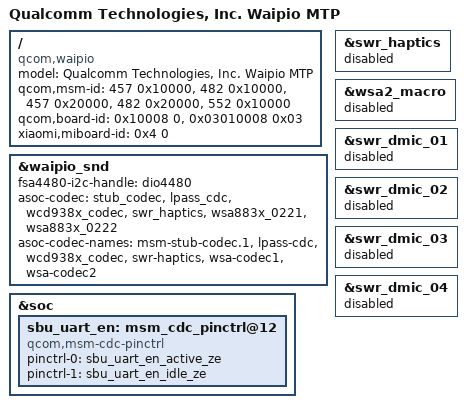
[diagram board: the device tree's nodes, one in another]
/dts-v1/;
/plugin/;

#include "xiaomi-sm8450-common.dtsi"

 / {
	model = "Qualcomm Technologies, Inc. Waipio MTP";
	compatible = "qcom,waipio";
	qcom,msm-id = <457 0x10000>, <482 0x10000>, <457 0x20000>, <482 0x20000>, <552 0x10000>;
	qcom,board-id = <0x10008 0>, <0x03010008 0x03>;
	xiaomi,miboard-id = <0x4 0>;
};

&waipio_snd {
	fsa4480-i2c-handle = <&dio4480>;
	asoc-codec = <&stub_codec>, <&lpass_cdc>,
			<&wcd938x_codec>, <&swr_haptics>,
			<&wsa883x_0221>, <&wsa883x_0222>;
	asoc-codec-names = "msm-stub-codec.1", "lpass-cdc",
			"wcd938x_codec", "swr-haptics",
			"wsa-codec1", "wsa-codec2";
};

&soc {
	sbu_uart_en: msm_cdc_pinctrl@12 {
		compatible = "qcom,msm-cdc-pinctrl";
		pinctrl-names = "aud_active", "aud_sleep";
		pinctrl-0 = <&sbu_uart_en_active_ze>;
		pinctrl-1 = <&sbu_uart_en_idle_ze>;
		#gpio-cells = <0>;
	};
};

&swr_haptics {
	status = "disabled";
};

&wsa2_macro {
        status = "disabled";
};

&swr_dmic_01 {
        status = "disabled";
};

&swr_dmic_02 {
        status = "disabled";
};

&swr_dmic_03 {
        status = "disabled";
};

&swr_dmic_04 {
        status = "disabled";
};
